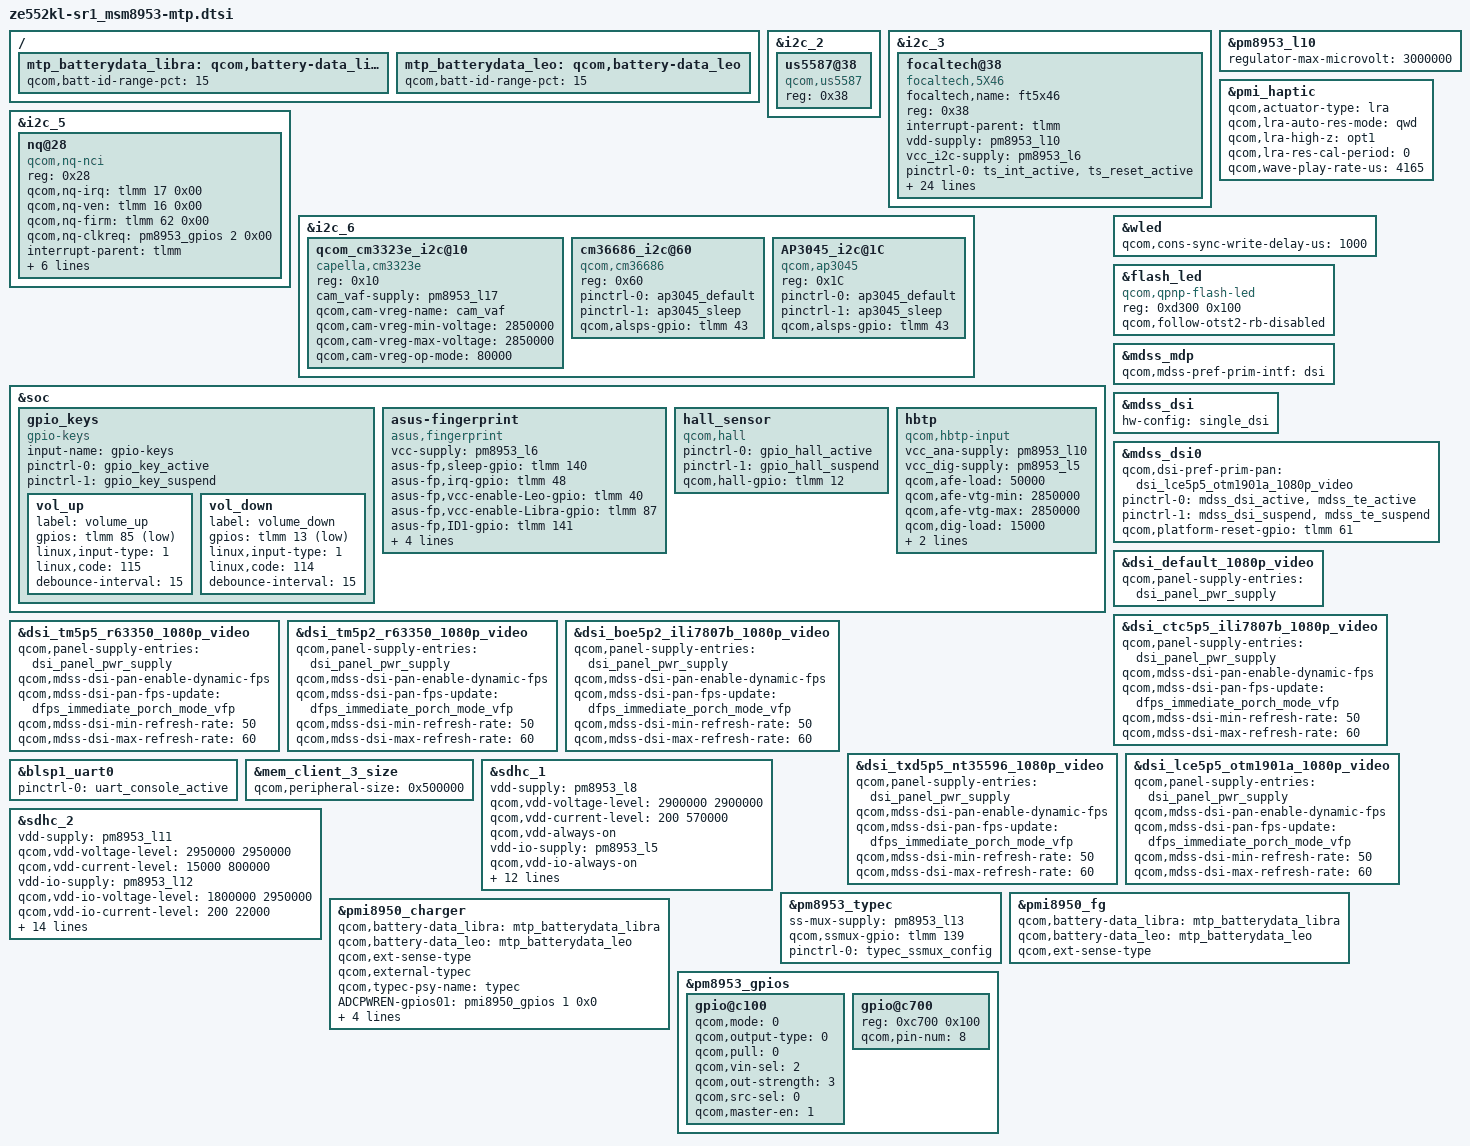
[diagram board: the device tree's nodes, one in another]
/*
 * Copyright (c) 2015-2017, The Linux Foundation. All rights reserved.
 *
 * This program is free software; you can redistribute it and/or modify
 * it under the terms of the GNU General Public License version 2 and
 * only version 2 as published by the Free Software Foundation.
 *
 * This program is distributed in the hope that it will be useful,
 * but WITHOUT ANY WARRANTY; without even the implied warranty of
 * MERCHANTABILITY or FITNESS FOR A PARTICULAR PURPOSE.  See the
 * GNU General Public License for more details.
 */

#include "ze552kl-sr1_msm8953-pinctrl.dtsi"
#include "ze552kl-sr1_msm8953-audio-mtp.dtsi"



&i2c_2 {
	us5587@38 {
		compatible = "qcom,us5587";
		reg = <0x38>;
		#address-cells = <1>;
		#size-cells = <0>;
	};
};

&i2c_3 { 
	focaltech@38 {
		compatible = "focaltech,5X46";
		focaltech,name = "ft5x46";
		reg = <0x38>;
		interrupt-parent = <&tlmm>;
		/*interrupts = <65 0x2008>;*/
		vdd-supply = <&pm8953_l10>;
		vcc_i2c-supply = <&pm8953_l6>;
		/* pins used by touchscreen */
		pinctrl-names = "pmx_ts_active","pmx_ts_suspend","pmx_ts_release";
		pinctrl-0 = <&ts_int_active &ts_reset_active>;
		pinctrl-1 = <&ts_int_suspend &ts_reset_suspend>;
		pinctrl-2 = <&ts_release>;
		focaltech,family-id = <0x36>;
		focaltech,reset-gpio = <&tlmm 64 0x0>;
		focaltech,irq-gpio = <&tlmm 65 0x2008>;
		/*focaltech,tpid1-gpio=<&tlmm 140 0x0>;
		focaltech,tpid0-gpio=<&tlmm 67 0x0>;*/
		focaltech,lcdid0-gpio=<&tlmm 59 0x0>;
		focaltech,lcdid1-gpio=<&tlmm 62 0x0>;
		focaltech,display-coords = <0 0 1080 1920>;
		focaltech,panel-coords = <0 0 1080 1920>;
		focaltech,button-map= <139 102 158>;
		focaltech,no-force-update;
		focaltech,i2c-pull-up;
		focaltech,group-id = <1>;
		focaltech,hard-reset-delay-ms = <20>;
		focaltech,soft-reset-delay-ms = <200>;
		focaltech,num-max-touches = <5>;
		focaltech,fw-delay-aa-ms = <30>;
		focaltech,fw-delay-55-ms = <30>;
		focaltech,fw-upgrade-id1 = <0x79>;
		focaltech,fw-upgrade-id2 = <0x18>;
		focaltech,fw-delay-readid-ms = <10>;
		focaltech,fw-delay-era-flsh-ms = <2000>;
		focaltech,fw-auto-cal;
		focaltech,ignore-id-check;

	};
};

&i2c_5 { /* BLSP2 QUP1 (NFC) */
	nq@28 {
		compatible = "qcom,nq-nci";
		reg = <0x28>;
		qcom,nq-irq = <&tlmm 17 0x00>;
		qcom,nq-ven = <&tlmm 16 0x00>;
		qcom,nq-firm = <&tlmm 62 0x00>;
		qcom,nq-clkreq = <&pm8953_gpios 2 0x00>;
		interrupt-parent = <&tlmm>;
		qcom,clk-src = "BBCLK2";
		interrupts = <17 0>;
		interrupt-names = "nfc_irq";
		pinctrl-names = "nfc_active", "nfc_suspend";
		pinctrl-0 = <&nfc_int_active &nfc_disable_active>;
		pinctrl-1 = <&nfc_int_suspend &nfc_disable_suspend>;
		clocks = <&clock_gcc clk_bb_clk2_pin>;
		clock-names = "ref_clk";
	};
};

&i2c_6 { /* BLSP2 QUP2 */
	/* ASUS_BSP: David: rgb sensor i2c ++*/
	qcom_cm3323e_i2c@10 {
		compatible = "capella,cm3323e";
		reg = <0x10>;
		cam_vaf-supply = <&pm8953_l17>;
		qcom,cam-vreg-name = "cam_vaf";
		qcom,cam-vreg-min-voltage = <2850000>;
		qcom,cam-vreg-max-voltage = <2850000>;
		qcom,cam-vreg-op-mode = <80000>;
	};
	/* ASUS_BSP: David: rgb sensor i2c --*/

	/* ASUS_BSP +++ ShawnHuang CM36686 */
	cm36686_i2c@60 {
		compatible = "qcom,cm36686";
		reg = <0x60>;
		pinctrl-names = "alsps_gpio_high","alsps_gpio_low";
		pinctrl-0 = <&ap3045_default>;
		pinctrl-1 = <&ap3045_sleep>;
		qcom,alsps-gpio = <&tlmm 43 0x0>;
	};
	/* ASUS_BSP --- ShawnHuang CM36686 */

	/* ASUS_BSP +++ ShawnHuang AP3045 */
	AP3045_i2c@1C {
		compatible = "qcom,ap3045";
		reg = <0x1C>;
		pinctrl-names = "alsps_gpio_high","alsps_gpio_low";
		pinctrl-0 = <&ap3045_default>;
		pinctrl-1 = <&ap3045_sleep>;
		qcom,alsps-gpio = <&tlmm 43 0x0>;
	};
	/* ASUS_BSP --- ShawnHuang AP3045 */
};

&pm8953_l10 {
	regulator-max-microvolt = <3000000>;
};

&soc {
	gpio_keys {
		compatible = "gpio-keys";
		input-name = "gpio-keys";
		pinctrl-names = "tlmm_gpio_key_active","tlmm_gpio_key_suspend";
		pinctrl-0 = <&gpio_key_active>;
		pinctrl-1 = <&gpio_key_suspend>;
/*
		camera_focus {
			label = "camera_focus";
			gpios = <&tlmm 87 0x1>;
			linux,input-type = <1>;
			linux,code = <0x210>;
			debounce-interval = <15>;
		};

		camera_snapshot {
			label = "camera_snapshot";
			gpios = <&tlmm 86 0x1>;
			linux,input-type = <1>;
			linux,code = <0x2fe>;
			debounce-interval = <15>;
		};
*/
		vol_up {
			label = "volume_up";
			gpios = <&tlmm 85 0x1>;
			linux,input-type = <1>;
			linux,code = <115>;
			debounce-interval = <15>;
		};
		
		vol_down {
			label = "volume_down";
			gpios = <&tlmm 13 0x1>;
			linux,input-type = <1>;
			linux,code = <114>;
			debounce-interval = <15>;
		};
	};
	// ASUS_BSP +++ Jacob Fingerprint sensor
	asus-fingerprint {
		compatible = "asus,fingerprint";
		vcc-supply = <&pm8953_l6>;
		asus-fp,sleep-gpio = <&tlmm 140 0x0>;
		asus-fp,irq-gpio = <&tlmm 48 0x2008>;
		asus-fp,vcc-enable-Leo-gpio = <&tlmm 40 0x0>;
		asus-fp,vcc-enable-Libra-gpio = <&tlmm 87 0x0>;
		asus-fp,ID1-gpio = <&tlmm 141 0x0>;
		asus-fp,ID2-gpio = <&tlmm 66 0x0>;

		/* Pinctrl Setting */
		qcom,use-pinctrl;
		pinctrl-names = "fp_default", "fp_sleep";
		pinctrl-0 = <&fp_int_active>;
		pinctrl-1 = <&fp_int_suspend>;
	};
	// ASUS_BSP --- Jacob Fingerprint sensor

	// ASUS_BSP +++ ShawnHuang HALL sensor
	hall_sensor {
		compatible = "qcom,hall";
		pinctrl-names = "hall_gpio_high","hall_gpio_low";
		pinctrl-0 = <&gpio_hall_active>;
		pinctrl-1 = <&gpio_hall_suspend>;			
		qcom,hall-gpio = <&tlmm 12 0x0>;
	};
	// ASUS_BSP --- ShawnHuang HALL sensor

	hbtp {
		compatible = "qcom,hbtp-input";
		vcc_ana-supply = <&pm8953_l10>;
		vcc_dig-supply = <&pm8953_l5>;
		qcom,afe-load = <50000>;
		qcom,afe-vtg-min = <2850000>;
		qcom,afe-vtg-max = <2850000>;
		qcom,dig-load = <15000>;
		qcom,dig-vtg-min = <1800000>;
		qcom,dig-vtg-max = <1800000>;
	};
};

&pmi_haptic{
	qcom,actuator-type = "lra";
	qcom,lra-auto-res-mode="qwd";
	qcom,lra-high-z="opt1";
	qcom,lra-res-cal-period = <0>;
	qcom,wave-play-rate-us = <4165>;
};

&wled {
	qcom,cons-sync-write-delay-us = <1000>;
};

&flash_led {
	compatible = "qcom,qpnp-flash-led";
	reg = <0xd300 0x100>;
	qcom,follow-otst2-rb-disabled;
};

#include "ze552kl-sr1_msm8953-mdss-panels.dtsi"

&mdss_mdp {
	qcom,mdss-pref-prim-intf = "dsi";
};

&mdss_dsi {
	hw-config = "single_dsi";
};

&mdss_dsi0 {
	//qcom,dsi-pref-prim-pan = <&dsi_truly_1080_vid>;
	//qcom,dsi-pref-prim-pan = <&dsi_default_1080p_video>;
	qcom,dsi-pref-prim-pan = <&dsi_ctc5p5_ili7807b_1080p_video>;
	qcom,dsi-pref-prim-pan = <&dsi_tm5p5_r63350_1080p_video>;
	qcom,dsi-pref-prim-pan = <&dsi_tm5p2_r63350_1080p_video>;
	qcom,dsi-pref-prim-pan = <&dsi_boe5p2_ili7807b_1080p_video>;
	qcom,dsi-pref-prim-pan = <&dsi_txd5p5_nt35596_1080p_video>;
	qcom,dsi-pref-prim-pan = <&dsi_lce5p5_otm1901a_1080p_video>;
	pinctrl-names = "mdss_default", "mdss_sleep";
	pinctrl-0 = <&mdss_dsi_active &mdss_te_active>;
	pinctrl-1 = <&mdss_dsi_suspend &mdss_te_suspend>;

	//qcom,platform-te-gpio = <&tlmm 24 0>;
	qcom,platform-reset-gpio = <&tlmm 61 0>;
	//qcom,platform-bklight-en-gpio = <&tlmm 59 0>;
};

/*&mdss_dsi1 {
	status = "disabled";
	qcom,dsi-pref-prim-pan = <&dsi_adv7533_1080p>;
	pinctrl-names = "mdss_default", "mdss_sleep";
	pinctrl-0 = <&mdss_dsi_active &mdss_te_active>;
	pinctrl-1 = <&mdss_dsi_suspend &mdss_te_suspend>;

	qcom,pluggable;
	qcom,platform-te-gpio = <&tlmm 24 0>;
	qcom,platform-reset-gpio = <&tlmm 61 0>;
	qcom,platform-bklight-en-gpio = <&tlmm 59 0>;
};*/

&dsi_default_1080p_video {
 	qcom,panel-supply-entries = <&dsi_panel_pwr_supply>;
};

&dsi_ctc5p5_ili7807b_1080p_video {
	qcom,panel-supply-entries = <&dsi_panel_pwr_supply>;
	qcom,mdss-dsi-pan-enable-dynamic-fps;
	qcom,mdss-dsi-pan-fps-update = "dfps_immediate_porch_mode_vfp";
	qcom,mdss-dsi-min-refresh-rate = <50>;
	qcom,mdss-dsi-max-refresh-rate = <60>;
};

&dsi_tm5p5_r63350_1080p_video {
	qcom,panel-supply-entries = <&dsi_panel_pwr_supply>;
	qcom,mdss-dsi-pan-enable-dynamic-fps;
	qcom,mdss-dsi-pan-fps-update = "dfps_immediate_porch_mode_vfp";
	qcom,mdss-dsi-min-refresh-rate = <50>;
	qcom,mdss-dsi-max-refresh-rate = <60>;
};

&dsi_tm5p2_r63350_1080p_video {
	qcom,panel-supply-entries = <&dsi_panel_pwr_supply>;
	qcom,mdss-dsi-pan-enable-dynamic-fps;
	qcom,mdss-dsi-pan-fps-update = "dfps_immediate_porch_mode_vfp";
	qcom,mdss-dsi-min-refresh-rate = <50>;
	qcom,mdss-dsi-max-refresh-rate = <60>;
};

&dsi_boe5p2_ili7807b_1080p_video {
	qcom,panel-supply-entries = <&dsi_panel_pwr_supply>;
	qcom,mdss-dsi-pan-enable-dynamic-fps;
	qcom,mdss-dsi-pan-fps-update = "dfps_immediate_porch_mode_vfp";
	qcom,mdss-dsi-min-refresh-rate = <50>;
	qcom,mdss-dsi-max-refresh-rate = <60>;
};

&dsi_txd5p5_nt35596_1080p_video {
	qcom,panel-supply-entries = <&dsi_panel_pwr_supply>;
	qcom,mdss-dsi-pan-enable-dynamic-fps;
	qcom,mdss-dsi-pan-fps-update = "dfps_immediate_porch_mode_vfp";
	qcom,mdss-dsi-min-refresh-rate = <50>;
	qcom,mdss-dsi-max-refresh-rate = <60>;
};

&dsi_lce5p5_otm1901a_1080p_video {
	qcom,panel-supply-entries = <&dsi_panel_pwr_supply>;
	qcom,mdss-dsi-pan-enable-dynamic-fps;
	qcom,mdss-dsi-pan-fps-update = "dfps_immediate_porch_mode_vfp";
	qcom,mdss-dsi-min-refresh-rate = <50>;
	qcom,mdss-dsi-max-refresh-rate = <60>;
};

/*&dsi_truly_1080_vid {
	qcom,panel-supply-entries = <&dsi_panel_pwr_supply>;
	qcom,mdss-dsi-pan-enable-dynamic-fps;
	qcom,mdss-dsi-pan-fps-update = "dfps_immediate_clk_mode";
};

&dsi_truly_1080_cmd {
	qcom,panel-supply-entries = <&dsi_panel_pwr_supply>;
	qcom,ulps-enabled;
	qcom,partial-update-enabled;
	qcom,panel-roi-alignment = <2 2 4 2 1080 2>;
};*/

&blsp1_uart0 {
	status = "ok";
	pinctrl-names = "default";
	pinctrl-0 = <&uart_console_active>;
};

&mem_client_3_size {
	qcom,peripheral-size = <0x500000>;
};

&sdhc_1 {
	/* device core power supply */
	vdd-supply = <&pm8953_l8>;
	qcom,vdd-voltage-level = <2900000 2900000>;
	qcom,vdd-current-level = <200 570000>;
	/*ASUS_BPS Deeo : make sure vdd power always on*/
	qcom,vdd-always-on;

	/* device communication power supply */
	vdd-io-supply = <&pm8953_l5>;
	qcom,vdd-io-always-on;
	qcom,vdd-io-lpm-sup;
	qcom,vdd-io-voltage-level = <1800000 1800000>;
	qcom,vdd-io-current-level = <200 325000>;

	pinctrl-names = "active", "sleep";
	pinctrl-0 = <&sdc1_clk_on &sdc1_cmd_on &sdc1_data_on  &sdc1_rclk_on>;
	pinctrl-1 = <&sdc1_clk_off &sdc1_cmd_off &sdc1_data_off &sdc1_rclk_off>;

	qcom,clk-rates = <400000 20000000 25000000 50000000 100000000 192000000
								384000000>;
	qcom,nonremovable;
	qcom,bus-speed-mode = "HS400_1p8v", "HS200_1p8v", "DDR_1p8v";

	status = "ok";
};

&sdhc_2 {
	/* device core power supply */
	vdd-supply = <&pm8953_l11>;
	qcom,vdd-voltage-level = <2950000 2950000>;
	qcom,vdd-current-level = <15000 800000>;

	/* device communication power supply */
	vdd-io-supply = <&pm8953_l12>;
	qcom,vdd-io-voltage-level = <1800000 2950000>;
	qcom,vdd-io-current-level = <200 22000>;

	pinctrl-names = "active", "sleep";
	pinctrl-0 = <&sdc2_clk_on &sdc2_cmd_on &sdc2_data_on &sdc2_cd_on>;
	pinctrl-1 = <&sdc2_clk_off &sdc2_cmd_off &sdc2_data_off>;

	#address-cells = <0>;
	interrupt-parent = <&sdhc_2>;
	interrupts = <0 1 2>;
	#interrupt-cells = <1>;
	interrupt-map-mask = <0xffffffff>;
	interrupt-map = <0 &intc 0 125 0
		1 &intc 0 221 0
		2 &tlmm 133 0>;
	interrupt-names = "hc_irq", "pwr_irq", "status_irq";
	cd-gpios = <&tlmm 133 0x1>;

	qcom,clk-rates = <400000 20000000 25000000 50000000 100000000
								200000000>;
	qcom,bus-speed-mode = "SDR12", "SDR25", "SDR50", "DDR50", "SDR104";

	status = "ok";
};

&pm8953_typec {
	ss-mux-supply = <&pm8953_l13>;
	qcom,ssmux-gpio = <&tlmm 139 GPIO_ACTIVE_HIGH>;
	pinctrl-names = "default";
	pinctrl-0 = <&typec_ssmux_config>;
};

/{
	mtp_batterydata_libra: qcom,battery-data_libra {
		qcom,batt-id-range-pct = <15>;
		#include "batterydata-Libra-2900mAh_4p38V-Coslight.dtsi"
		#include "batterydata-Libra-2900mAh_4p38V-LG.dtsi"
		#include "batterydata-Libra-2900mAh_4p38V-SMP.dtsi"
		#include "batterydata-Libra-Generic.dtsi"
	};
	mtp_batterydata_leo: qcom,battery-data_leo {
		qcom,batt-id-range-pct = <15>;
		#include "batterydata-Leo-2530mAh_4p38V-SMP.dtsi"
		#include "batterydata-Leo-Generic.dtsi"
	};
};

&pmi8950_fg {
	qcom,battery-data_libra = <&mtp_batterydata_libra>;
	qcom,battery-data_leo = <&mtp_batterydata_leo>;
	qcom,ext-sense-type;
};

&pmi8950_charger {
	qcom,battery-data_libra = <&mtp_batterydata_libra>;
	qcom,battery-data_leo = <&mtp_batterydata_leo>;
	qcom,ext-sense-type;
	//qcom,chg-led-sw-controls;    //ASUS_BSP Deeo : remove for LED
	//qcom,chg-led-support;        //ASUS_BSP Deeo : remove for LED
	qcom,external-typec;
	qcom,typec-psy-name = "typec";
	ADCPWREN-gpios01 = <&pmi8950_gpios 1 0x0>;
	USBID_CTRL-gpios08 = <&pm8953_gpios 8 0x0>;
	DPM_SW_EN-gpios134 = <&tlmm 134 0x0>;
	ADC_VDD_EN-gpios99 = <&tlmm 99 0x1>;
	USB_TEMP_ALERT-gpios90 = <&tlmm 90 0x1>;
};

&pm8953_gpios {
	/* GPIO 2 (NFC_CLK_REQ) */
	gpio@c100 {
		qcom,mode = <0>;
		qcom,output-type = <0>;
		qcom,pull = <0>;
		qcom,vin-sel = <2>;
		qcom,out-strength = <3>;
		qcom,src-sel = <0>;
		qcom,master-en = <1>;
		status = "okay";
	};
	/* GPIO 8 (USBID_CTRL) */
	gpio@c700 {
		reg = <0xc700 0x100>;
		qcom,pin-num = <8>;
		status = "okay";
	};
};
